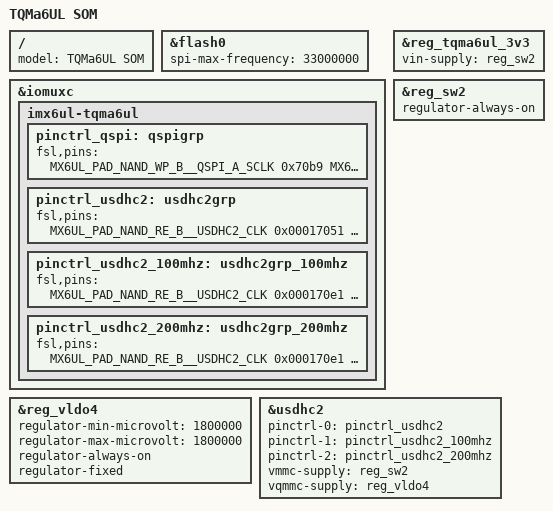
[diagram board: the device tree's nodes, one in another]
/*
 * Copyright 2016 Marco Felsch, TQ Systems GmbH
 *
 * The code contained herein is licensed under the GNU General Public
 * License. You may obtain a copy of the GNU General Public License
 * Version 2 or later at the following locations:
 *
 * http://www.opensource.org/licenses/gpl-license.html
 * http://www.gnu.org/copyleft/gpl.html
 */

#include <dt-bindings/input/input.h>
#include "imx6ul-tqma6ulxl.dtsi"

/ {
	model = "TQMa6UL SOM";
};

&flash0 {
	spi-max-frequency = <33000000>;
};

&iomuxc {
	imx6ul-tqma6ul {
		pinctrl_qspi: qspigrp {
			fsl,pins = <
				MX6UL_PAD_NAND_WP_B__QSPI_A_SCLK      0x70b9
				MX6UL_PAD_NAND_READY_B__QSPI_A_DATA00 0x70b9
				MX6UL_PAD_NAND_CE0_B__QSPI_A_DATA01   0x70b9
				MX6UL_PAD_NAND_CE1_B__QSPI_A_DATA02   0x70b9
				MX6UL_PAD_NAND_CLE__QSPI_A_DATA03     0x70b9
				MX6UL_PAD_NAND_DQS__QSPI_A_SS0_B      0x70a1
			>;
		};

		pinctrl_usdhc2: usdhc2grp {
			fsl,pins = <
				MX6UL_PAD_NAND_RE_B__USDHC2_CLK		0x00017051
				MX6UL_PAD_NAND_WE_B__USDHC2_CMD		0x00017051
				MX6UL_PAD_NAND_DATA00__USDHC2_DATA0	0x00017051
				MX6UL_PAD_NAND_DATA01__USDHC2_DATA1	0x00017051
				MX6UL_PAD_NAND_DATA02__USDHC2_DATA2	0x00017051
				MX6UL_PAD_NAND_DATA03__USDHC2_DATA3	0x00017051
				MX6UL_PAD_NAND_DATA04__USDHC2_DATA4	0x00017051
				MX6UL_PAD_NAND_DATA05__USDHC2_DATA5	0x00017051
				MX6UL_PAD_NAND_DATA06__USDHC2_DATA6	0x00017051
				MX6UL_PAD_NAND_DATA07__USDHC2_DATA7	0x00017051
				/* rst */
				MX6UL_PAD_NAND_ALE__GPIO4_IO10		0x0001b051
			>;
		};

		pinctrl_usdhc2_100mhz: usdhc2grp_100mhz {
			fsl,pins = <
				MX6UL_PAD_NAND_RE_B__USDHC2_CLK		0x000170e1
				MX6UL_PAD_NAND_WE_B__USDHC2_CMD		0x000170f1
				MX6UL_PAD_NAND_DATA00__USDHC2_DATA0	0x000170f1
				MX6UL_PAD_NAND_DATA01__USDHC2_DATA1	0x000170f1
				MX6UL_PAD_NAND_DATA02__USDHC2_DATA2	0x000170f1
				MX6UL_PAD_NAND_DATA03__USDHC2_DATA3	0x000170f1
				MX6UL_PAD_NAND_DATA04__USDHC2_DATA4	0x000170f1
				MX6UL_PAD_NAND_DATA05__USDHC2_DATA5	0x000170f1
				MX6UL_PAD_NAND_DATA06__USDHC2_DATA6	0x000170f1
				MX6UL_PAD_NAND_DATA07__USDHC2_DATA7	0x000170f1
				/* rst */
				MX6UL_PAD_NAND_ALE__GPIO4_IO10		0x0001b051
			>;
		};

		pinctrl_usdhc2_200mhz: usdhc2grp_200mhz {
			fsl,pins = <
				MX6UL_PAD_NAND_RE_B__USDHC2_CLK		0x000170e1
				MX6UL_PAD_NAND_WE_B__USDHC2_CMD		0x000170f1
				MX6UL_PAD_NAND_DATA00__USDHC2_DATA0	0x000170f1
				MX6UL_PAD_NAND_DATA01__USDHC2_DATA1	0x000170f1
				MX6UL_PAD_NAND_DATA02__USDHC2_DATA2	0x000170f1
				MX6UL_PAD_NAND_DATA03__USDHC2_DATA3	0x000170f1
				MX6UL_PAD_NAND_DATA04__USDHC2_DATA4	0x000170f1
				MX6UL_PAD_NAND_DATA05__USDHC2_DATA5	0x000170f1
				MX6UL_PAD_NAND_DATA06__USDHC2_DATA6	0x000170f1
				MX6UL_PAD_NAND_DATA07__USDHC2_DATA7	0x000170f1
				/* rst */
				MX6UL_PAD_NAND_ALE__GPIO4_IO10		0x0001b051
			>;
		};
	};
};

&reg_tqma6ul_3v3 {
	vin-supply = <&reg_sw2>;
};

&reg_sw2 {
	regulator-always-on;
};

&reg_vldo4 {
	regulator-min-microvolt = <1800000>;
	regulator-max-microvolt = <1800000>;
	regulator-always-on;
	regulator-fixed;
};

/* eMMC */
&usdhc2 {
	pinctrl-names = "default", "state_100mhz" , "state_200mhz";
	pinctrl-0 = <&pinctrl_usdhc2>;
	pinctrl-1 = <&pinctrl_usdhc2_100mhz>;
	pinctrl-2 = <&pinctrl_usdhc2_200mhz>;

	vmmc-supply = <&reg_sw2>;
	vqmmc-supply = <&reg_vldo4>;
	/delete-property/ no-1-8-v;
};
